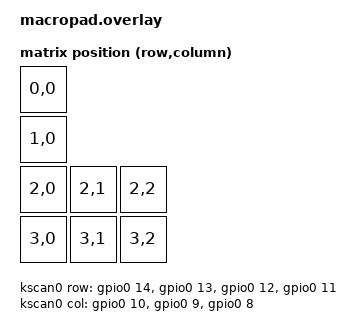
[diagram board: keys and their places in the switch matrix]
// This file was generated from a template. Edit it to match your keyboard.
// See https://zmk.dev/docs/development/hardware-integration/new-shield for more
// instructions.

#include <dt-bindings/zmk/matrix_transform.h>

#include "macropad-layouts.dtsi"

/ {
    chosen {
        zmk,physical-layout = &default_layout;
        zephyr,console = &cdc_acm_uart0;
    };

    kscan0: kscan0 {
        compatible = "zmk,kscan-gpio-matrix";
        wakeup-source;
        diode-direction = "col2row";

        col-gpios
            = <&gpio0 10  GPIO_ACTIVE_HIGH>
            , <&gpio0 9   GPIO_ACTIVE_HIGH>
            , <&gpio0 8   GPIO_ACTIVE_HIGH>
            ;

        row-gpios
            = <&gpio0 14 (GPIO_ACTIVE_HIGH | GPIO_PULL_DOWN)>
            , <&gpio0 13 (GPIO_ACTIVE_HIGH | GPIO_PULL_DOWN)>
            , <&gpio0 12 (GPIO_ACTIVE_HIGH | GPIO_PULL_DOWN)>
            , <&gpio0 11 (GPIO_ACTIVE_HIGH | GPIO_PULL_DOWN)>
            ;
    };

    default_transform: default_transform {
        compatible = "zmk,matrix-transform";
        columns = <3>;
        rows = <4>;

        map = <
            /* Row 0: 1 key */
            RC(0,0)
            /* Row 1: 1 key */
            RC(1,0)
            /* Row 2: 3 keys */
            RC(2,0) RC(2,1) RC(2,2)
            /* Row 3: 3 key */
            RC(3,0) RC(3,1) RC(3,2)
        >;
    };

    as5600_listener: as5600_listener {
        compatible = "zmk,input-listener";
        device = <&as5600>;
        input-processors = <&zip_scroll_scaler (-1) 3>;
    };
};

&i2c1 {
	status = "okay";
	pinctrl-0 = <&i2c1_custom>;
	pinctrl-names = "default";
	clock-frequency = <I2C_BITRATE_STANDARD>;

	as5600: as5600@36 {
		compatible = "zmk,input-ams-as5600";
		status = "okay";
		reg = <0x36>;
	};
};

&pinctrl {
	i2c1_custom: i2c1_custom {
		group1 {
			pinmux = <I2C1_SDA_P6>;
			input-enable;
		};

		group2 {
			pinmux = <I2C1_SCL_P7>;
			input-enable;
		};
	};
};

&zephyr_udc0 {
    status = "okay";

	cdc_acm_uart0: cdc_acm_uart0 {
		compatible = "zephyr,cdc-acm-uart";
	};
};

&usbd {
    status = "okay";
};
